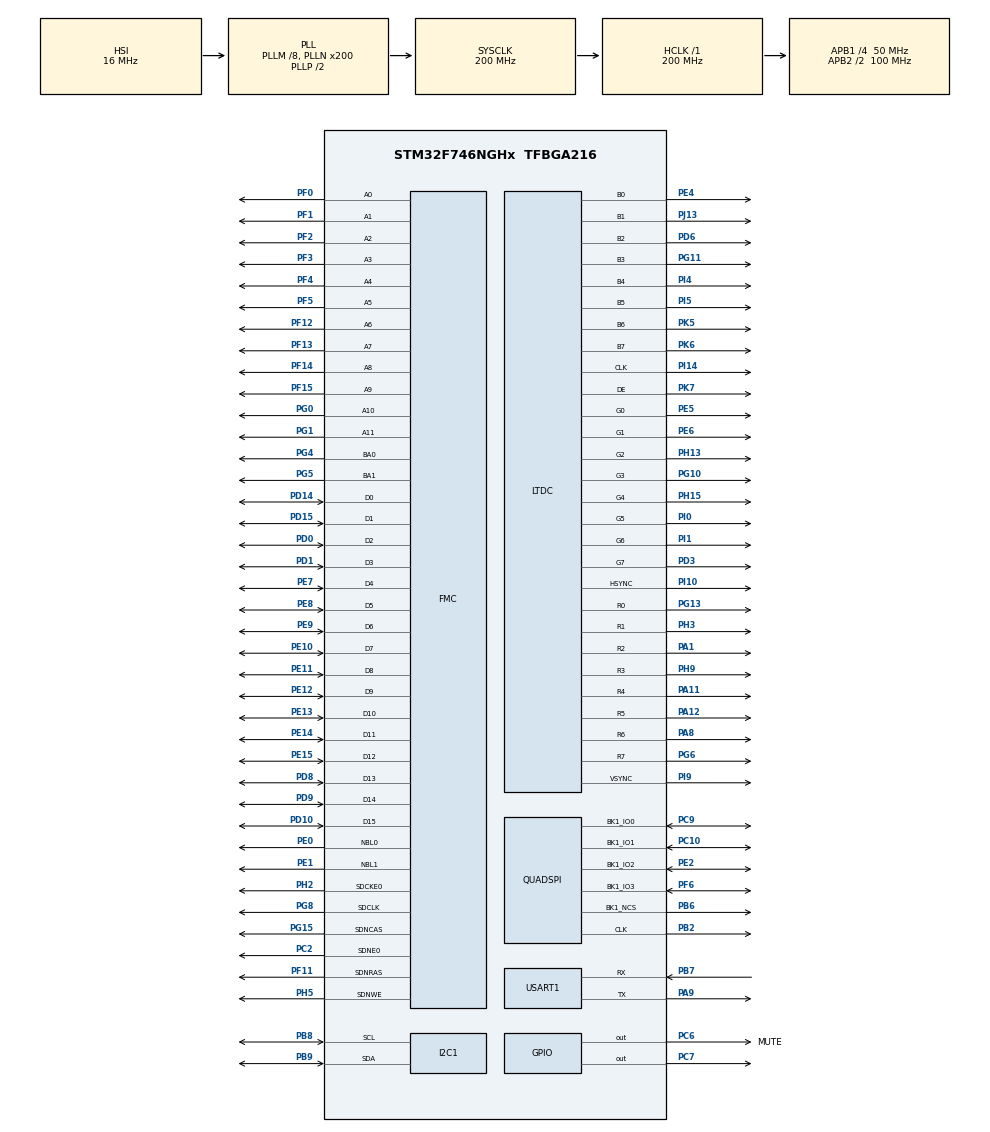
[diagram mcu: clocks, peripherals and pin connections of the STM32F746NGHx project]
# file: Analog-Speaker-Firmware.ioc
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I2C1.Timing=0x00C0EAFF
Mcu.Family=STM32F7
Mcu.Name=STM32F746NGHx
Mcu.Package=TFBGA216
NVIC.PriorityGroup=NVIC_PRIORITYGROUP_4
PA1.Mode=RGB888
PA1.Signal=LTDC_R2
PA11.Mode=RGB888
PA11.Signal=LTDC_R4
PA12.Mode=RGB888
PA12.Signal=LTDC_R5
PA8.Mode=RGB888
PA8.Signal=LTDC_R6
PA9.Mode=Asynchronous
PA9.Signal=USART1_TX
PB2.Mode=Single Bank 1
PB2.Signal=QUADSPI_CLK
PB6.Mode=Single Bank 1
PB6.Signal=QUADSPI_BK1_NCS
PB7.Mode=Asynchronous
PB7.Signal=USART1_RX
PB8.Mode=I2C
PB8.Signal=I2C1_SCL
PB9.Mode=I2C
PB9.Signal=I2C1_SDA
PC10.Mode=Single Bank 1
PC10.Signal=QUADSPI_BK1_IO1
PC14/OSC32_IN.Mode=LSE-External-Oscillator
PC14/OSC32_IN.Signal=RCC_OSC32_IN
PC15/OSC32_OUT.Mode=LSE-External-Oscillator
PC15/OSC32_OUT.Signal=RCC_OSC32_OUT
PC2.Mode=SdramChipSelect1_1
PC2.Signal=FMC_SDNE0
PC6.GPIO_Label=MUTE
PC6.Signal=GPIO_Output
PC7.Signal=GPIO_Output
PC9.Mode=Single Bank 1
PC9.Signal=QUADSPI_BK1_IO0
PD0.Signal=FMC_D2_DA2
PD1.Signal=FMC_D3_DA3
PD10.Signal=FMC_D15_DA15
PD14.Signal=FMC_D0_DA0
PD15.Signal=FMC_D1_DA1
PD3.Mode=RGB888
PD3.Signal=LTDC_G7
PD6.Mode=RGB888
PD6.Signal=LTDC_B2
PD8.Signal=FMC_D13_DA13
PD9.Signal=FMC_D14_DA14
PE0.Signal=FMC_NBL0
PE1.Signal=FMC_NBL1
PE10.Signal=FMC_D7_DA7
PE11.Signal=FMC_D8_DA8
PE12.Signal=FMC_D9_DA9
PE13.Signal=FMC_D10_DA10
PE14.Signal=FMC_D11_DA11
PE15.Signal=FMC_D12_DA12
PE2.Mode=Single Bank 1
PE2.Signal=QUADSPI_BK1_IO2
PE4.Mode=RGB888
PE4.Signal=LTDC_B0
PE5.Mode=RGB888
PE5.Signal=LTDC_G0
PE6.Mode=RGB888
PE6.Signal=LTDC_G1
PE7.Signal=FMC_D4_DA4
PE8.Signal=FMC_D5_DA5
PE9.Signal=FMC_D6_DA6
PF0.Signal=FMC_A0
PF1.Signal=FMC_A1
PF11.Signal=FMC_SDNRAS
PF12.Signal=FMC_A6
PF13.Signal=FMC_A7
PF14.Signal=FMC_A8
PF15.Signal=FMC_A9
PF2.Signal=FMC_A2
PF3.Signal=FMC_A3
PF4.Signal=FMC_A4
PF5.Signal=FMC_A5
PF6.Mode=Single Bank 1
PF6.Signal=QUADSPI_BK1_IO3
PG0.Signal=FMC_A10
PG1.Signal=FMC_A11
PG10.Mode=RGB888
PG10.Signal=LTDC_G3
PG11.Mode=RGB888
PG11.Signal=LTDC_B3
PG13.Mode=RGB888
PG13.Signal=LTDC_R0
PG15.Signal=FMC_SDNCAS
PG4.Signal=FMC_A14_BA0
PG5.Signal=FMC_A15_BA1
PG6.Mode=RGB888
PG6.Signal=LTDC_R7
PG8.Signal=FMC_SDCLK
PH0/OSC_IN.Mode=HSE-External-Oscillator
PH0/OSC_IN.Signal=RCC_OSC_IN
PH1/OSC_OUT.Mode=HSE-External-Oscillator
PH1/OSC_OUT.Signal=RCC_OSC_OUT
PH13.Mode=RGB888
PH13.Signal=LTDC_G2
PH15.Mode=RGB888
PH15.Signal=LTDC_G4
PH2.Mode=SdramChipSelect1_1
PH2.Signal=FMC_SDCKE0
PH3.Mode=RGB888
PH3.Signal=LTDC_R1
PH5.Signal=FMC_SDNWE
PH9.Mode=RGB888
PH9.Signal=LTDC_R3
PI0.Mode=RGB888
PI0.Signal=LTDC_G5
PI1.Mode=RGB888
PI1.Signal=LTDC_G6
PI10.Mode=RGB888
PI10.Signal=LTDC_HSYNC
PI14.Mode=RGB888
PI14.Signal=LTDC_CLK
PI4.Mode=RGB888
PI4.Signal=LTDC_B4
PI5.Mode=RGB888
PI5.Signal=LTDC_B5
PI9.Mode=RGB888
PI9.Signal=LTDC_VSYNC
PJ13.Mode=RGB888
PJ13.Signal=LTDC_B1
PK5.Mode=RGB888
PK5.Signal=LTDC_B6
PK6.Mode=RGB888
PK6.Signal=LTDC_B7
PK7.Mode=RGB888
PK7.Signal=LTDC_DE
ProjectManager.HeapSize=0x200
ProjectManager.StackSize=0x400
ProjectManager.TargetToolchain=STM32CubeIDE
RCC.AHBFreq_Value=200000000
RCC.APB1CLKDivider=RCC_HCLK_DIV4
RCC.APB1Freq_Value=50000000
RCC.APB1TimFreq_Value=100000000
RCC.APB2CLKDivider=RCC_HCLK_DIV2
RCC.APB2Freq_Value=100000000
RCC.APB2TimFreq_Value=200000000
RCC.CortexFreq_Value=200000000
RCC.HCLKFreq_Value=200000000
RCC.HSE_VALUE=25000000
RCC.HSI_VALUE=16000000
RCC.PLLM=8
RCC.PLLN=200
RCC.PLLSAIN=96
RCC.PLLSAIR=5
RCC.PLLSAIRDiv=RCC_PLLSAIDIVR_4
RCC.PLLSourceVirtual=RCC_PLLSOURCE_HSI
RCC.SYSCLKFreq_VALUE=200000000
RCC.SYSCLKSource=RCC_SYSCLKSOURCE_PLLCLK
RCC.USBFreq_Value=200000000
RCC.VCOOutputFreq_Value=400000000
SH.FMC_A0.0=FMC_A0,12b-sda1
SH.FMC_A1.0=FMC_A1,12b-sda1
SH.FMC_A10.0=FMC_A10,12b-sda1
SH.FMC_A11.0=FMC_A11,12b-sda1
SH.FMC_A14_BA0.0=FMC_BA0,FourSdramBanks1
SH.FMC_A15_BA1.0=FMC_BA1,FourSdramBanks1
SH.FMC_A2.0=FMC_A2,12b-sda1
SH.FMC_A3.0=FMC_A3,12b-sda1
SH.FMC_A4.0=FMC_A4,12b-sda1
SH.FMC_A5.0=FMC_A5,12b-sda1
SH.FMC_A6.0=FMC_A6,12b-sda1
SH.FMC_A7.0=FMC_A7,12b-sda1
SH.FMC_A8.0=FMC_A8,12b-sda1
SH.FMC_A9.0=FMC_A9,12b-sda1
SH.FMC_D0_DA0.0=FMC_D0,sd-16b-d1
SH.FMC_D10_DA10.0=FMC_D10,sd-16b-d1
SH.FMC_D11_DA11.0=FMC_D11,sd-16b-d1
SH.FMC_D12_DA12.0=FMC_D12,sd-16b-d1
SH.FMC_D13_DA13.0=FMC_D13,sd-16b-d1
SH.FMC_D14_DA14.0=FMC_D14,sd-16b-d1
SH.FMC_D15_DA15.0=FMC_D15,sd-16b-d1
SH.FMC_D1_DA1.0=FMC_D1,sd-16b-d1
SH.FMC_D2_DA2.0=FMC_D2,sd-16b-d1
SH.FMC_D3_DA3.0=FMC_D3,sd-16b-d1
SH.FMC_D4_DA4.0=FMC_D4,sd-16b-d1
SH.FMC_D5_DA5.0=FMC_D5,sd-16b-d1
SH.FMC_D6_DA6.0=FMC_D6,sd-16b-d1
SH.FMC_D7_DA7.0=FMC_D7,sd-16b-d1
SH.FMC_D8_DA8.0=FMC_D8,sd-16b-d1
SH.FMC_D9_DA9.0=FMC_D9,sd-16b-d1
SH.FMC_NBL0.0=FMC_NBL0,Sd2ByteEnable1
SH.FMC_NBL1.0=FMC_NBL1,Sd2ByteEnable1
SH.FMC_SDCLK.0=FMC_SDCLK,12b-sda1
SH.FMC_SDNCAS.0=FMC_SDNCAS,12b-sda1
SH.FMC_SDNRAS.0=FMC_SDNRAS,12b-sda1
SH.FMC_SDNWE.0=FMC_SDNWE,12b-sda1
USART1.VirtualMode-Asynchronous=VM_ASYNC
VP_DMA2D_VS_DMA2D.Mode=DMA2D_Activate
board=STM32F746G-DISCO

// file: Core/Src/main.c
/* USER CODE BEGIN Header */
/**
  ******************************************************************************
  * @file           : main.c
  * @brief          : Main program body
  ******************************************************************************
  * @attention
  *
  * Copyright (c) 2024 STMicroelectronics.
  * All rights reserved.
  *
  * This software is licensed under terms that can be found in the LICENSE file
  * in the root directory of this software component.
  * If no LICENSE file comes with this software, it is provided AS-IS.
  *
  ******************************************************************************
  */
/* USER CODE END Header */
#include "main.h"

/* USER CODE BEGIN Includes */
#include "stm32f7508_discovery.h"
#include "stm32f7508_discovery_lcd.h"
#include "stm32f7508_discovery_sdram.h"
#include "stm32f7508_discovery_ts.h"

#include "string.h"
/* USER CODE END Includes */

DMA2D_HandleTypeDef hdma2d;

I2C_HandleTypeDef hi2c1;

LTDC_HandleTypeDef hltdc;

QSPI_HandleTypeDef hqspi;

UART_HandleTypeDef huart1;

SDRAM_HandleTypeDef hsdram1;

/* USER CODE BEGIN PV */
static const uint8_t DS3930E_ADDR=0x50<<1;
static const uint8_t REG_FADER1=0xF0;
static const uint8_t REG_FADER2=0xF1;
static const uint8_t REG_FADER3=0xF2;
static const uint8_t REG_FADER4=0xF3;
static const uint8_t REG_FADER5=0xF4;
/* USER CODE END PV */

void SystemClock_Config(void);
static void MX_GPIO_Init(void);
static void MX_I2C1_Init(void);
static void MX_LTDC_Init(void);
static void MX_USART1_UART_Init(void);
static void MX_QUADSPI_Init(void);
static void MX_FMC_Init(void);
static void MX_DMA2D_Init(void);

/* USER CODE BEGIN 0 */
void writetopot(uint8_t buf[12], HAL_StatusTypeDef ret){
	ret=HAL_I2C_Master_Transmit(&hi2c1, DS3930E_ADDR, buf, 2, HAL_MAX_DELAY);//write 2 bytes to I2C IC

	return;
}
void intscreen(){//draw faders and borders to the screen
	BSP_LCD_SelectLayer(0);//set background to white
	BSP_LCD_SetTextColor(LCD_COLOR_WHITE);
	BSP_LCD_FillRect(0, 0, 480, 272);

	for(int i=1;i<6;i++){//draw faders
		  BSP_LCD_SelectLayer(0);
		  BSP_LCD_SetTextColor(LCD_COLOR_GRAY);
		  BSP_LCD_FillRect(((480+50)/6*i)-50, 36, 50, 200);
		  if(i<5)
			  BSP_LCD_FillRect(((480+50)/6*i)+17, 0, 5, 272);

		  BSP_LCD_SelectLayer(1);
		  BSP_LCD_SetTextColor(LCD_COLOR_DARKGRAY);
		  BSP_LCD_FillRect(((480+50)/6*i)-60, 123, 70, 25);
		  BSP_LCD_SetTextColor(LCD_COLOR_WHITE);
		  BSP_LCD_FillRect(((480+50)/6*i)-55, 133, 60, 5);
	  }

	  BSP_LCD_SelectLayer(0);//draw borders
	  BSP_LCD_SetTextColor(LCD_COLOR_DARKGRAY);
	  BSP_LCD_FillRect(0, 0, 10, 272);
	  BSP_LCD_FillRect(470, 0, 10, 272);
	  BSP_LCD_FillRect(0, 0, 480, 10);
	  BSP_LCD_FillRect(0, 262, 480, 10);
}
uint8_t fadercontrol(int fadernr,int cordY, uint8_t buf[12], HAL_StatusTypeDef ret, int transparent){
	static int pastcord=0;
	static uint8_t FaderValue;
	if(pastcord!=cordY){//check if fader got moved
		BSP_LCD_SelectLayer(1);
		BSP_LCD_SetTextColor(transparent);//clear past fader on screen
		BSP_LCD_FillRect(((480+50)/6*fadernr)-60, 10, 70, 262);
		if(cordY > 36 && cordY < 236){//if fader is within the sliders position just draw to screen
			BSP_LCD_SetTextColor(LCD_COLOR_DARKGRAY);
			BSP_LCD_FillRect(((480+50)/6*fadernr)-60, cordY-13, 70, 25);
			BSP_LCD_SetTextColor(LCD_COLOR_WHITE);
			BSP_LCD_FillRect(((480+50)/6*fadernr)-55, cordY-3, 60, 5);
			FaderValue=(((cordY-36)*127)/200);
		}
		else if(cordY < 36){//if fader is above top edge draw to top most position
			BSP_LCD_SetTextColor(LCD_COLOR_DARKGRAY);
			BSP_LCD_FillRect(((480+50)/6*fadernr)-60, 36-13, 70, 25);
			BSP_LCD_SetTextColor(LCD_COLOR_WHITE);
			BSP_LCD_FillRect(((480+50)/6*fadernr)-55, 36-3, 60, 5);
			FaderValue=0;

		}
		else if(cordY > 236){//if fader is below bottom edge draw to bottom most position
			BSP_LCD_SetTextColor(LCD_COLOR_DARKGRAY);
			BSP_LCD_FillRect(((480+50)/6*fadernr)-60, 236-13, 70, 25);
			BSP_LCD_SetTextColor(LCD_COLOR_WHITE);
			BSP_LCD_FillRect(((480+50)/6*fadernr)-55, 236-3, 60, 5);
			FaderValue=127;
		}

		switch (fadernr){//save address register of the fader thats being held
		case 1:
			buf[0]=REG_FADER1;
			break;
		case 2:
			buf[0]=REG_FADER2;
			break;
		case 3:
			buf[0]=REG_FADER3;
			break;
		case 4:
			buf[0]=REG_FADER4;
			break;
		case 5:
			buf[0]=REG_FADER5;
			break;
		}

		//FaderValue=127+FaderValue;//flip the 8 bit value(might delete later depends)
		FaderValue=255-FaderValue;
		buf[1]=FaderValue;

		writetopot(buf, ret);//write to potentiometer via I2C
	}
	pastcord=cordY;

	return(FaderValue);
}

/* USER CODE END 0 */

int main(void)
{
  /* USER CODE BEGIN 1 */
	HAL_StatusTypeDef ret = HAL_OK;
	TS_StateTypeDef TS_State;
	unsigned int transparent=0x00000000;
	uint8_t buf[12];
  /* USER CODE END 1 */

  /* MCU Configuration--------------------------------------------------------*/

  /* Reset of all peripherals, Initializes the Flash interface and the Systick. */
  HAL_Init();

  /* Configure the system clock */
  SystemClock_Config();

  /* Initialize all configured peripherals */
  MX_GPIO_Init();
  MX_I2C1_Init();
  MX_LTDC_Init();
  MX_USART1_UART_Init();
  MX_QUADSPI_Init();
  MX_FMC_Init();
  MX_DMA2D_Init();
  /* USER CODE BEGIN 2 */
  /*QSPI INIT*/

  BSP_LCD_Init();
  BSP_LCD_LayerDefaultInit(1, LCD_FB_START_ADDRESS);
  BSP_LCD_LayerDefaultInit(0, LCD_FB_START_ADDRESS+(480*272*4));
  /* Enable the LCD */
  BSP_LCD_DisplayOn();
  /* Select the LCD Background Layer  */
  BSP_LCD_SelectLayer(0);
  /* Clear the Background Layer */
  BSP_LCD_Clear(transparent);
  BSP_LCD_SelectLayer(1);
  /* Clear the foreground Layer */
  BSP_LCD_Clear(transparent);
  /* Some sign */
  BSP_LCD_SetBackColor(LCD_COLOR_GRAY);
  BSP_LCD_SetTextColor(LCD_COLOR_RED);
  BSP_LCD_SetFont(&Font12);

  BSP_TS_Init(480,272);

  intscreen();
  uint8_t test;
  /* USER CODE END 2 */

  /* Infinite loop */
  while (1)
  {

    /* USER CODE BEGIN 3 */
	  BSP_TS_GetState(&TS_State);
	  if(TS_State.touchDetected > 0){//see if there is a touch on the screen
		  if(TS_State.touchX[0] > 0 && TS_State.touchX[0] < 105){//see if said touch is this fader's part of the screen
			  while(TS_State.touchDetected > 0){//as long as the press is held stay within loop
				  test=fadercontrol(1,TS_State.touchY[0], buf, ret, transparent);

				  //test code
				  /*
				  if(test<127){
					  BSP_LCD_SelectLayer(0);
					  BSP_LCD_SetTextColor(LCD_COLOR_RED);
					  BSP_LCD_FillRect(0, 0, 480, 272);
				  }
				  else if (test<=255){
					  BSP_LCD_SelectLayer(0);
					  BSP_LCD_SetTextColor(LCD_COLOR_GREEN);
					  BSP_LCD_FillRect(0, 0, 480, 272);
				  }
				   */

				  BSP_TS_GetState(&TS_State);
			  }
		  }
		  else if(TS_State.touchX[0] > 106 && TS_State.touchX[0] < 194){//see if said touch is this fader's part of the screen
			  while(TS_State.touchDetected > 0){//as long as the press is held stay within loop
				  fadercontrol(2,TS_State.touchY[0], buf, ret, transparent);
				  BSP_TS_GetState(&TS_State);
			  }
		  }
		  else if(TS_State.touchX[0] > 195 && TS_State.touchX[0] < 282){//see if said touch is this fader's part of the screen
			  while(TS_State.touchDetected > 0){//as long as the press is held stay within loop
				  fadercontrol(3,TS_State.touchY[0], buf, ret, transparent);
				  BSP_TS_GetState(&TS_State);
			  }
		  }
		  else if(TS_State.touchX[0] > 283 && TS_State.touchX[0] < 370){//see if said touch is this fader's part of the screen
			  while(TS_State.touchDetected > 0){//as long as the press is held stay within loop
				  fadercontrol(4,TS_State.touchY[0], buf, ret, transparent);
				  BSP_TS_GetState(&TS_State);
			  }
		  }
		  else if(TS_State.touchX[0] > 371 && TS_State.touchX[0] < 480){//see if said touch is this fader's part of the screen
			  while(TS_State.touchDetected > 0){//as long as the press is held stay within loop
				  fadercontrol(5,TS_State.touchY[0], buf, ret, transparent);
				  BSP_TS_GetState(&TS_State);
			  }
		  }
	  }
  }
  /* USER CODE END 3 */
}

void SystemClock_Config(void)
{
  RCC_OscInitTypeDef RCC_OscInitStruct = {0};
  RCC_ClkInitTypeDef RCC_ClkInitStruct = {0};

  /** Configure LSE Drive Capability
  */
  HAL_PWR_EnableBkUpAccess();

  /** Configure the main internal regulator output voltage
  */
  __HAL_RCC_PWR_CLK_ENABLE();
  __HAL_PWR_VOLTAGESCALING_CONFIG(PWR_REGULATOR_VOLTAGE_SCALE1);

  /** Initializes the RCC Oscillators according to the specified parameters
  * in the RCC_OscInitTypeDef structure.
  */
  RCC_OscInitStruct.OscillatorType = RCC_OSCILLATORTYPE_HSI;
  RCC_OscInitStruct.HSIState = RCC_HSI_ON;
  RCC_OscInitStruct.HSICalibrationValue = RCC_HSICALIBRATION_DEFAULT;
  RCC_OscInitStruct.PLL.PLLState = RCC_PLL_ON;
  RCC_OscInitStruct.PLL.PLLSource = RCC_PLLSOURCE_HSI;
  RCC_OscInitStruct.PLL.PLLM = 8;
  RCC_OscInitStruct.PLL.PLLN = 200;
  RCC_OscInitStruct.PLL.PLLP = RCC_PLLP_DIV2;
  RCC_OscInitStruct.PLL.PLLQ = 2;
  if (HAL_RCC_OscConfig(&RCC_OscInitStruct) != HAL_OK)
  {
    Error_Handler();
  }

  /** Activate the Over-Drive mode
  */
  if (HAL_PWREx_EnableOverDrive() != HAL_OK)
  {
    Error_Handler();
  }

  /** Initializes the CPU, AHB and APB buses clocks
  */
  RCC_ClkInitStruct.ClockType = RCC_CLOCKTYPE_HCLK|RCC_CLOCKTYPE_SYSCLK
                              |RCC_CLOCKTYPE_PCLK1|RCC_CLOCKTYPE_PCLK2;
  RCC_ClkInitStruct.SYSCLKSource = RCC_SYSCLKSOURCE_PLLCLK;
  RCC_ClkInitStruct.AHBCLKDivider = RCC_SYSCLK_DIV1;
  RCC_ClkInitStruct.APB1CLKDivider = RCC_HCLK_DIV4;
  RCC_ClkInitStruct.APB2CLKDivider = RCC_HCLK_DIV2;

  if (HAL_RCC_ClockConfig(&RCC_ClkInitStruct, FLASH_LATENCY_6) != HAL_OK)
  {
    Error_Handler();
  }
}

static void MX_DMA2D_Init(void)
{

  hdma2d.Instance = DMA2D;
  hdma2d.Init.Mode = DMA2D_M2M;
  hdma2d.Init.ColorMode = DMA2D_OUTPUT_ARGB8888;
  hdma2d.Init.OutputOffset = 0;
  hdma2d.LayerCfg[1].InputOffset = 0;
  hdma2d.LayerCfg[1].InputColorMode = DMA2D_INPUT_ARGB8888;
  hdma2d.LayerCfg[1].AlphaMode = DMA2D_NO_MODIF_ALPHA;
  hdma2d.LayerCfg[1].InputAlpha = 0;
  if (HAL_DMA2D_Init(&hdma2d) != HAL_OK)
  {
    Error_Handler();
  }
  if (HAL_DMA2D_ConfigLayer(&hdma2d, 1) != HAL_OK)
  {
    Error_Handler();
  }

}

static void MX_I2C1_Init(void)
{

  hi2c1.Instance = I2C1;
  hi2c1.Init.Timing = 0x00C0EAFF;
  hi2c1.Init.OwnAddress1 = 0;
  hi2c1.Init.AddressingMode = I2C_ADDRESSINGMODE_7BIT;
  hi2c1.Init.DualAddressMode = I2C_DUALADDRESS_DISABLE;
  hi2c1.Init.OwnAddress2 = 0;
  hi2c1.Init.OwnAddress2Masks = I2C_OA2_NOMASK;
  hi2c1.Init.GeneralCallMode = I2C_GENERALCALL_DISABLE;
  hi2c1.Init.NoStretchMode = I2C_NOSTRETCH_DISABLE;
  if (HAL_I2C_Init(&hi2c1) != HAL_OK)
  {
    Error_Handler();
  }

  /** Configure Analogue filter
  */
  if (HAL_I2CEx_ConfigAnalogFilter(&hi2c1, I2C_ANALOGFILTER_ENABLE) != HAL_OK)
  {
    Error_Handler();
  }

  /** Configure Digital filter
  */
  if (HAL_I2CEx_ConfigDigitalFilter(&hi2c1, 0) != HAL_OK)
  {
    Error_Handler();
  }

}

static void MX_LTDC_Init(void)
{

  LTDC_LayerCfgTypeDef pLayerCfg = {0};
  LTDC_LayerCfgTypeDef pLayerCfg1 = {0};

  hltdc.Instance = LTDC;
  hltdc.Init.HSPolarity = LTDC_HSPOLARITY_AL;
  hltdc.Init.VSPolarity = LTDC_VSPOLARITY_AL;
  hltdc.Init.DEPolarity = LTDC_DEPOLARITY_AL;
  hltdc.Init.PCPolarity = LTDC_PCPOLARITY_IPC;
  hltdc.Init.HorizontalSync = 7;
  hltdc.Init.VerticalSync = 3;
  hltdc.Init.AccumulatedHBP = 14;
  hltdc.Init.AccumulatedVBP = 5;
  hltdc.Init.AccumulatedActiveW = 654;
  hltdc.Init.AccumulatedActiveH = 485;
  hltdc.Init.TotalWidth = 660;
  hltdc.Init.TotalHeigh = 487;
  hltdc.Init.Backcolor.Blue = 0;
  hltdc.Init.Backcolor.Green = 0;
  hltdc.Init.Backcolor.Red = 0;
  if (HAL_LTDC_Init(&hltdc) != HAL_OK)
  {
    Error_Handler();
  }
  pLayerCfg.WindowX0 = 0;
  pLayerCfg.WindowX1 = 0;
  pLayerCfg.WindowY0 = 0;
  pLayerCfg.WindowY1 = 0;
  pLayerCfg.PixelFormat = LTDC_PIXEL_FORMAT_ARGB8888;
  pLayerCfg.Alpha = 0;
  pLayerCfg.Alpha0 = 0;
  pLayerCfg.BlendingFactor1 = LTDC_BLENDING_FACTOR1_CA;
  pLayerCfg.BlendingFactor2 = LTDC_BLENDING_FACTOR2_CA;
  pLayerCfg.FBStartAdress = 0;
  pLayerCfg.ImageWidth = 0;
  pLayerCfg.ImageHeight = 0;
  pLayerCfg.Backcolor.Blue = 0;
  pLayerCfg.Backcolor.Green = 0;
  pLayerCfg.Backcolor.Red = 0;
  if (HAL_LTDC_ConfigLayer(&hltdc, &pLayerCfg, 0) != HAL_OK)
  {
    Error_Handler();
  }
  pLayerCfg1.WindowX0 = 0;
  pLayerCfg1.WindowX1 = 0;
  pLayerCfg1.WindowY0 = 0;
  pLayerCfg1.WindowY1 = 0;
  pLayerCfg1.PixelFormat = LTDC_PIXEL_FORMAT_ARGB8888;
  pLayerCfg1.Alpha = 0;
  pLayerCfg1.Alpha0 = 0;
  pLayerCfg1.BlendingFactor1 = LTDC_BLENDING_FACTOR1_CA;
  pLayerCfg1.BlendingFactor2 = LTDC_BLENDING_FACTOR2_CA;
  pLayerCfg1.FBStartAdress = 0;
  pLayerCfg1.ImageWidth = 0;
  pLayerCfg1.ImageHeight = 0;
  pLayerCfg1.Backcolor.Blue = 0;
  pLayerCfg1.Backcolor.Green = 0;
  pLayerCfg1.Backcolor.Red = 0;
  if (HAL_LTDC_ConfigLayer(&hltdc, &pLayerCfg1, 1) != HAL_OK)
  {
    Error_Handler();
  }

}

static void MX_QUADSPI_Init(void)
{

  /* QUADSPI parameter configuration*/
  hqspi.Instance = QUADSPI;
  hqspi.Init.ClockPrescaler = 255;
  hqspi.Init.FifoThreshold = 1;
  hqspi.Init.SampleShifting = QSPI_SAMPLE_SHIFTING_NONE;
  hqspi.Init.FlashSize = 1;
  hqspi.Init.ChipSelectHighTime = QSPI_CS_HIGH_TIME_1_CYCLE;
  hqspi.Init.ClockMode = QSPI_CLOCK_MODE_0;
  hqspi.Init.FlashID = QSPI_FLASH_ID_1;
  hqspi.Init.DualFlash = QSPI_DUALFLASH_DISABLE;
  if (HAL_QSPI_Init(&hqspi) != HAL_OK)
  {
    Error_Handler();
  }

}

static void MX_USART1_UART_Init(void)
{

  huart1.Instance = USART1;
  huart1.Init.BaudRate = 115200;
  huart1.Init.WordLength = UART_WORDLENGTH_8B;
  huart1.Init.StopBits = UART_STOPBITS_1;
  huart1.Init.Parity = UART_PARITY_NONE;
  huart1.Init.Mode = UART_MODE_TX_RX;
  huart1.Init.HwFlowCtl = UART_HWCONTROL_NONE;
  huart1.Init.OverSampling = UART_OVERSAMPLING_16;
  huart1.Init.OneBitSampling = UART_ONE_BIT_SAMPLE_DISABLE;
  huart1.AdvancedInit.AdvFeatureInit = UART_ADVFEATURE_NO_INIT;
  if (HAL_UART_Init(&huart1) != HAL_OK)
  {
    Error_Handler();
  }

}

/* FMC initialization function */
static void MX_FMC_Init(void)
{

  FMC_SDRAM_TimingTypeDef SdramTiming = {0};

  /** Perform the SDRAM1 memory initialization sequence
  */
  hsdram1.Instance = FMC_SDRAM_DEVICE;
  /* hsdram1.Init */
  hsdram1.Init.SDBank = FMC_SDRAM_BANK1;
  hsdram1.Init.ColumnBitsNumber = FMC_SDRAM_COLUMN_BITS_NUM_8;
  hsdram1.Init.RowBitsNumber = FMC_SDRAM_ROW_BITS_NUM_12;
  hsdram1.Init.MemoryDataWidth = FMC_SDRAM_MEM_BUS_WIDTH_16;
  hsdram1.Init.InternalBankNumber = FMC_SDRAM_INTERN_BANKS_NUM_4;
  hsdram1.Init.CASLatency = FMC_SDRAM_CAS_LATENCY_1;
  hsdram1.Init.WriteProtection = FMC_SDRAM_WRITE_PROTECTION_DISABLE;
  hsdram1.Init.SDClockPeriod = FMC_SDRAM_CLOCK_DISABLE;
  hsdram1.Init.ReadBurst = FMC_SDRAM_RBURST_DISABLE;
  hsdram1.Init.ReadPipeDelay = FMC_SDRAM_RPIPE_DELAY_0;
  /* SdramTiming */
  SdramTiming.LoadToActiveDelay = 16;
  SdramTiming.ExitSelfRefreshDelay = 16;
  SdramTiming.SelfRefreshTime = 16;
  SdramTiming.RowCycleDelay = 16;
  SdramTiming.WriteRecoveryTime = 16;
  SdramTiming.RPDelay = 16;
  SdramTiming.RCDDelay = 16;

  if (HAL_SDRAM_Init(&hsdram1, &SdramTiming) != HAL_OK)
  {
    Error_Handler( );
  }

}

static void MX_GPIO_Init(void)
{
  GPIO_InitTypeDef GPIO_InitStruct = {0};

  /* GPIO Ports Clock Enable */
  __HAL_RCC_GPIOE_CLK_ENABLE();
  __HAL_RCC_GPIOB_CLK_ENABLE();
  __HAL_RCC_GPIOG_CLK_ENABLE();
  __HAL_RCC_GPIOJ_CLK_ENABLE();
  __HAL_RCC_GPIOD_CLK_ENABLE();
  __HAL_RCC_GPIOC_CLK_ENABLE();
  __HAL_RCC_GPIOA_CLK_ENABLE();
  __HAL_RCC_GPIOI_CLK_ENABLE();
  __HAL_RCC_GPIOK_CLK_ENABLE();
  __HAL_RCC_GPIOF_CLK_ENABLE();
  __HAL_RCC_GPIOH_CLK_ENABLE();

  /*Configure GPIO pin Output Level */
  HAL_GPIO_WritePin(GPIOC, GPIO_PIN_7|MUTE_Pin, GPIO_PIN_RESET);

  /*Configure GPIO pins : PC7 MUTE_Pin */
  GPIO_InitStruct.Pin = GPIO_PIN_7|MUTE_Pin;
  GPIO_InitStruct.Mode = GPIO_MODE_OUTPUT_PP;
  GPIO_InitStruct.Pull = GPIO_NOPULL;
  GPIO_InitStruct.Speed = GPIO_SPEED_FREQ_LOW;
  HAL_GPIO_Init(GPIOC, &GPIO_InitStruct);

}

void Error_Handler(void)
{
  __disable_irq();
  while (1)
  {
  }
}
